# CY8C5287AXI_LP095 register map
File version: 0.1
Registers are 8-bit, read-write, no defined reset value unless marked. A register's access mark holds for its fields unless they carry their own. Offsets are from the block's base; [hi:lo] are bit positions; {n}, {i} and the like mark numbered series; 'fields as' and 'values as' point back to an identical list.

## UART
Base 0x00000000
0x40006421 RX_UART_RX_ADDRESS1 — RX Address1 Register
0x40006431 RX_UART_RX_ADDRESS2 — RX Address2 Register
0x40006441 RX_UART_RX_DATA — RX Data Register
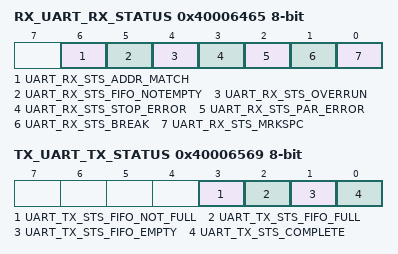
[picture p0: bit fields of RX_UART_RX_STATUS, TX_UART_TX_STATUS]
0x40006465 RX_UART_RX_STATUS — RX status register
  [6] UART_RX_STS_ADDR_MATCH ro, [5] UART_RX_STS_FIFO_NOTEMPTY ro, [4] UART_RX_STS_OVERRUN ro, [3] UART_RX_STS_STOP_ERROR ro, [2] UART_RX_STS_PAR_ERROR ro, [1] UART_RX_STS_BREAK ro, [0] UART_RX_STS_MRKSPC ro
0x40006548 TX_UART_TX_DATA — TX Data Register
0x40006569 TX_UART_TX_STATUS — TX status register
  [3] UART_TX_STS_FIFO_NOT_FULL ro, [2] UART_TX_STS_FIFO_FULL ro, [1] UART_TX_STS_FIFO_EMPTY ro, [0] UART_TX_STS_COMPLETE ro

## USBUART — USBFS
Base 0x00000000
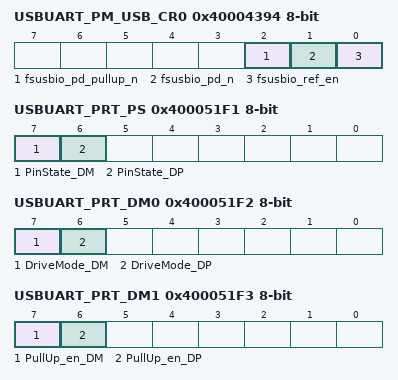
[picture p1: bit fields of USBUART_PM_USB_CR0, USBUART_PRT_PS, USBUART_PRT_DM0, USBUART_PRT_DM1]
0x40004394 USBUART_PM_USB_CR0 — USB Power Mode Control Register 0
  [2] fsusbio_pd_pullup_n, [1] fsusbio_pd_n, [0] fsusbio_ref_en
0x400043A5 USBUART_PM_ACT_CFG — Active Power Mode Configuration Register
0x400043B5 USBUART_PM_STBY_CFG — Standby Power Mode Configuration Register
0x400051F1 USBUART_PRT_PS — Port Pin State Register
  [7] PinState_DM ro, [6] PinState_DP ro
0x400051F2 USBUART_PRT_DM0 — Port Drive Mode Register
  [7] DriveMode_DM, [6] DriveMode_DP
0x400051F3 USBUART_PRT_DM1 — Port Drive Mode Register
  [7] PullUp_en_DM, [6] PullUp_en_DP
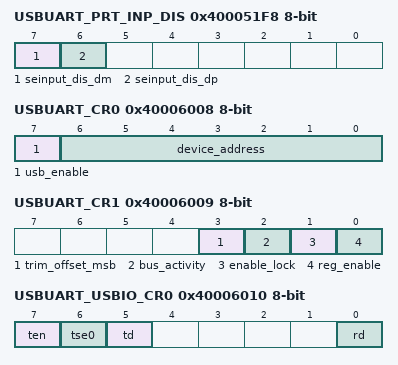
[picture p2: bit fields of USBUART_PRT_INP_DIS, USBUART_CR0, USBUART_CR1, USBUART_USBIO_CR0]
0x400051F8 USBUART_PRT_INP_DIS — Input buffer disable override
  [7] seinput_dis_dm, [6] seinput_dis_dp
0x40006000 USBUART_EP0_DR0 — bmRequestType
0x40006001 USBUART_EP0_DR1 — bRequest
0x40006002 USBUART_EP0_DR2 — wValueLo
0x40006003 USBUART_EP0_DR3 — wValueHi
0x40006004 USBUART_EP0_DR4 — wIndexLo
0x40006005 USBUART_EP0_DR5 — wIndexHi
0x40006006 USBUART_EP0_DR6 — lengthLo
0x40006007 USBUART_EP0_DR7 — lengthHi
0x40006008 USBUART_CR0 — USB Control Register 0
  [7] usb_enable, [6:0] device_address ro
0x40006009 USBUART_CR1 — USB Control Register 1
  [3] trim_offset_msb, [2] bus_activity, [1] enable_lock, [0] reg_enable
{0x40005FFE+0x10*i} USBUART_SIE_EP{i}_CR0 (i=1..8) — The Endpoint{i} Control Register
0x40006010 USBUART_USBIO_CR0 — USBIO Control Register 0
  [7] ten, [6] tse0, [5] td, [0] rd ro
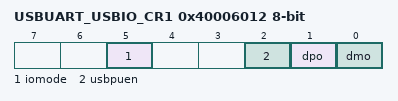
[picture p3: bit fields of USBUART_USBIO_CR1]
0x40006012 USBUART_USBIO_CR1 — USBIO Control Register 1
  [5] iomode, [2] usbpuen, [1] dpo ro, [0] dmo ro
0x4000608C USBUART_BUF_SIZE — Dedicated Endpoint Buffer Size Register
0x4000608E USBUART_EP_ACTIVE — Endpoint Active Indication Register
0x4000608F USBUART_EP_TYPE — Endpoint Type (IN/OUT) Indication
0x4000609D USBUART_USB_CLK_EN — USB Block Clock Enable Register

## CSD — CapSense
Base 0x00000000
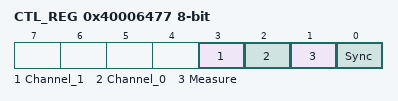
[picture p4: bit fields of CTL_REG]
0x40006477 CTL_REG — CapSense Control Register
  [3] Channel_1 ro — Channel 1 Enable
    0=Disabled (Channel 1 scanning is disabled); 1=Enabled (Channel 1 scanning is enabled)
  [2] Channel_0 ro — Channel 0 Enable
    0=Disabled (Channel 0 scanning is disabled); 1=Enabled (Channel 0 scanning is enabled)
  [1] Measure ro — Measurement Enable
    0=Disabled (Capacitance measurement is disabled); 1=Enabled (Capacitance measurement is enabled)
  [0] Sync ro — Reset Digital and Pre-Charge Clocks
    0=Disabled (Clocks are in the reset state); 1=Enabled (Clocks are enabled)
0x40006598 ScanSpeed_CTL_REG — CapSense Clock Prescaler Control Register
  [3] Counter ro — Clock Prescaler Enable
    0=Disabled (Prescaler counter is disabled); 1=Enabled (Prescaler counter is enabled)

## CSD_IdacCH0
Base 0x00000000
0x400043A8 IDAC8_PM_ACT_CFG — Active Power Mode Configuration Register 8
  [3:0] en_dac — Enable DAC block(s). Populated subsystems are counted from the LSB.
0x400043B8 IDAC8_PM_STBY_CFG — Standby Power Mode Configuration Register 8
  fields as IDAC8_PM_ACT_CFG
0x40004608 IDAC8_TR
  [7:0] tr — 8 Calibration bits
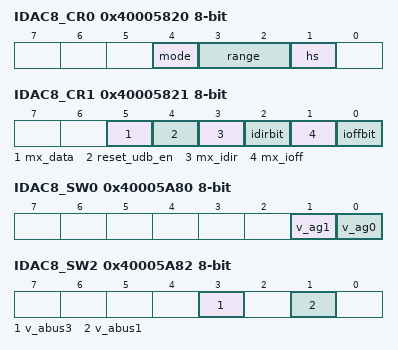
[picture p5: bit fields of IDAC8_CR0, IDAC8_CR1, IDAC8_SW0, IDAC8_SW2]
0x40005820 IDAC8_CR0 — DAC Block Control Register 0
  [4] mode ro — Mode Bit
    0=DAC_MODE_V (voltage DAC); 1=DAC_MODE_I (current DAC)
  [3:2] range — Ranges for mode=0 (VDAC) and mode=1 (IDAC)
    0=DAC_RANGE_0 (x0=0V to 4*vref (1.024V); 0 to 31.875uA); 1=DAC_RANGE_1 (x1=0V to 16*vref (4.096V); 0 to 255uA); 2=DAC_RANGE_2 (x0=0V to 4*vref (1.024V); 0 to 2.040mA); 3=DAC_RANGE_3 (x1=0V to 16*vref (4.096V); not used)
  [1] hs — High Speed Bit
    0=DAC_HS_LOWPOWER (regular (low power)); 1=DAC_HS_HIGHSPEED (high speed (higher power))
0x40005821 IDAC8_CR1 — DAC Block Control Register 1
  [5] mx_data — Select DATA source
    0=MX_DATA_REG (Select register source); 1=MX_DATA_UDB (Select UDB source)
  [4] reset_udb_en — DAC reset enable
    0=RESET_UDB_EN_DISABLE (Disable DAC Reset Source from UDB); 1=RESET_UDB_EN_ENABLE (Enable DAC Reset Source from UDB)
  [3] mx_idir — Mux selection for DAC current direction control
    0=MX_IDIR_REG (Register source idirbit selected); 1=MX_IDIR_UDB (UDB ictrl selected)
  [2] idirbit — register source for DAC current direction
  [1] mx_ioff — Mux selection for DAC current off control
    0=MX_IOFF_REG (Register source ioffbit selected); 1=MX_IOFF_UDB (UDB ictrl selected)
  [0] ioffbit — register source for DAC current off
0x40005A80 IDAC8_SW0 — DAC Analog Routing Register 0
  [1] v_ag1 — Connect voltage output to analog global of same side
    0=AG_NC (not connected); 1=AG_CONNECTED (Connect to Analog Global)
  [0] v_ag0 — Connect voltage output to analog global of same side
    values as v_ag1
0x40005A82 IDAC8_SW2 — DAC Analog Routing Register 2
  [3] v_abus3 — Connect voltage output to analog (local) bus of the same side
    0=ABUS_NC (not connected); 1=ABUS_CONNECTED (Connect to Analog (local) Bus)
  [1] v_abus1 — Connect voltage output to analog (local) bus of the same side
    values as v_abus3
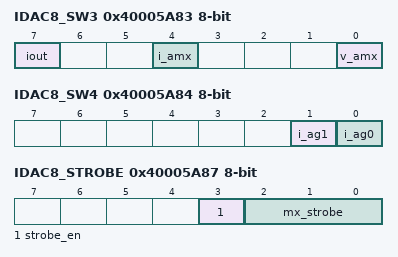
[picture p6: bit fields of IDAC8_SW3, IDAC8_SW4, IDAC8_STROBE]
0x40005A83 IDAC8_SW3 — DAC Analog Routing Register 3
  [7] iout — Connect current output to pad
    0=IOUT_NC (not connected); 1=IOUT_CONNECT (Connect to pad)
  [4] i_amx — Connect current output to Analog Mux Bus
    0=AMX_NC (not connected); 1=AMX_CONNECTED (Connect to AMUXBUS)
  [0] v_amx — Connect voltage output to Analog Mux Bus
    values as i_amx
0x40005A84 IDAC8_SW4 — DAC Analog Routing Register 4
  [1] i_ag1 — Connect current output to analog global of same side
    values as IDAC8_SW0.v_ag1
  [0] i_ag0 — Connect current output to analog global of same side
    values as IDAC8_SW0.v_ag1
0x40005A87 IDAC8_STROBE — DAC Strobe Register
  [3] strobe_en — Strobe gating control
    0=disable strobe; 1=enable strobe
  [2:0] mx_strobe — Strobe source selection
    0=MX_STROBE_BUSWRITE (Select bus write strobe source); 1=MX_STROBE_UDB_SRC (Select UDB strobe source); 2=MX_STROBE_NC_2 (NC); 3=MX_STROBE_NC_3 (NC); {v}=MX_STROBE_CLK_A{v-4}_DIG (Select clk_a{v-4}_dig) (v=4..7)
0x40005B80 IDAC8_D — DAC Data Register
  [7:0] data — 8 DAC Data bits
